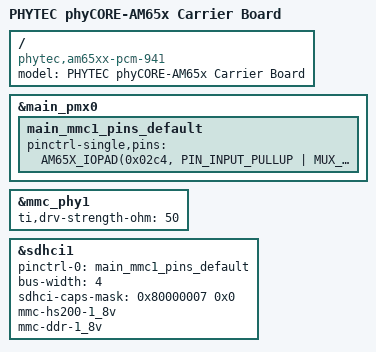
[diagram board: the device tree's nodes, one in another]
// SPDX-License-Identifier: GPL-2.0
/*
 * Copyright (C) 2018 PHYTEC America, LLC - https://www.phytec.com
 */

/ {
	model = "PHYTEC phyCORE-AM65x Carrier Board";
	compatible = "phytec,am65xx-pcm-941", "phytec,am65xx-phycore-som", "ti,am654";
};

&main_pmx0 {
	main_mmc1_pins_default: main_mmc1_pins_default {
		pinctrl-single,pins = <
			AM65X_IOPAD(0x02c4, PIN_INPUT_PULLUP | MUX_MODE0)	/* (D27) MMC1_DAT3 */
			AM65X_IOPAD(0x02c8, PIN_INPUT_PULLUP | MUX_MODE0)	/* (D26) MMC1_DAT2 */
			AM65X_IOPAD(0x02cc, PIN_INPUT_PULLUP | MUX_MODE0)	/* (E27) MMC1_DAT1 */
			AM65X_IOPAD(0x02d0, PIN_INPUT_PULLUP | MUX_MODE0)	/* (D28) MMC1_DAT0 */
			AM65X_IOPAD(0x02d4, PIN_INPUT_PULLDOWN | MUX_MODE0)	/* (C27) MMC1_CLK */
			AM65X_IOPAD(0x02d8, PIN_INPUT_PULLUP | MUX_MODE0)	/* (C28) MMC1_CMD */
			AM65X_IOPAD(0x02dc, PIN_INPUT_PULLUP | MUX_MODE0)	/* (B24) MMC1_SDCD */
		>;
	};
};

&mmc_phy1 {
	status = "okay";
	ti,drv-strength-ohm = <50>;
};

&sdhci1 {
	status = "okay";
	pinctrl-names = "default";
	pinctrl-0 = <&main_mmc1_pins_default>;
	bus-width = <4>;
	sdhci-caps-mask = <0x80000007 0x0>;
	mmc-hs200-1_8v;
	mmc-ddr-1_8v;
};
